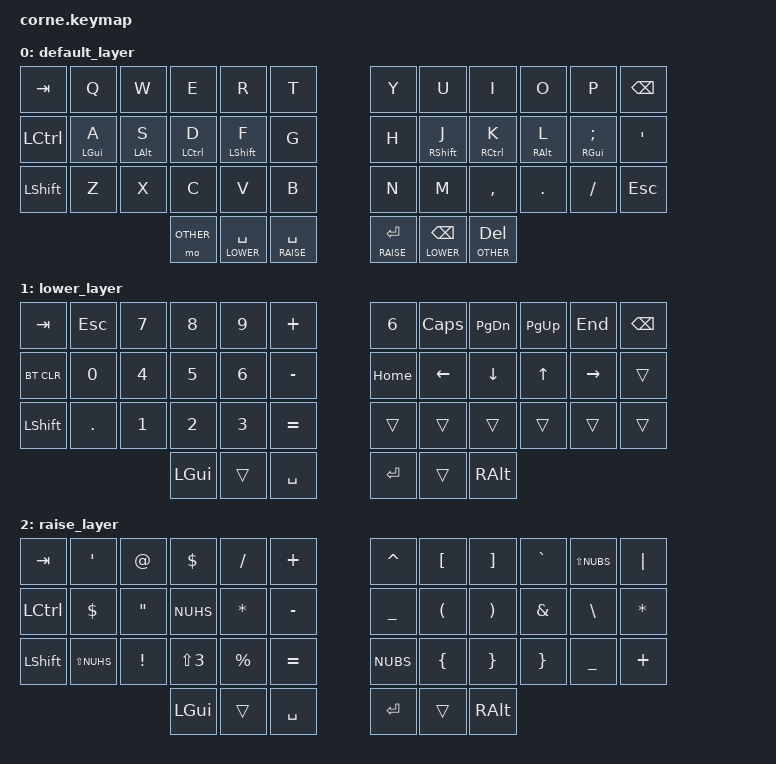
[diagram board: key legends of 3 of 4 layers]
/*
 * Copyright (c) 2020 The ZMK Contributors
 *
 * SPDX-License-Identifier: MIT
 */

#include <behaviors.dtsi>
#include <dt-bindings/zmk/keys.h>
#include <dt-bindings/zmk/bt.h>
#include <dt-bindings/zmk/outputs.h>

#define DEFAULT 0
#define LOWER   1
#define RAISE   2
#define OTHER   3

&lt {
    quick-tap-ms = <200>;
    tapping-term-ms = <200>;
};

/ {
    behaviors {
        hm: homerow_mods {
            compatible = "zmk,behavior-hold-tap";
            #binding-cells = <2>;
            tapping-term-ms = <200>;
            quick-tap-ms = <200>;
            require-prior-idle-ms = <125>;
            flavor = "tap-preferred";
            bindings = <&kp>, <&kp>;
        };
    };
    combos {
        compatible = "zmk,combos";
        combo_tab {
            timeout-ms = <50>;
            key-positions = <7 8>;
            bindings = <&kp TAB>;
        };
        combo_esc { 
            timeout-ms = <50>;
            key-positions = <3 4>;
            bindings = <&kp ESC>;
        };
        combo_caps_wd { 
            timeout-ms = <50>;
            key-positions = <2 3>;
            bindings = <&caps_word>;
        };
        combo_caps { 
            timeout-ms = <50>;
            key-positions = <8 9>;
            bindings = <&kp CAPS>;
        };
    };

        keymap {
                compatible = "zmk,keymap";

                default_layer {
                        bindings = <
   &kp TAB   &kp Q      &kp W      &kp E       &kp R        &kp T   &kp Y &kp U         &kp I           &kp O        &kp P         &kp BSPC
   &kp LCTRL &hm LGUI A &hm LALT S &hm LCTRL D &hm LSHIFT F &kp G   &kp H &hm RSHIFT J  &hm RCTRL K     &hm RALT L   &hm RGUI SEMI &kp SQT
   &kp LSHFT &kp Z      &kp X      &kp C       &kp V        &kp B   &kp N &kp M         &kp COMMA       &kp DOT      &kp FSLH      &kp ESC
                  &mo OTHER &lt LOWER SPACE &lt RAISE SPACE   &lt RAISE RET &lt LOWER BKSP &lt OTHER DEL
                        >;
                };
                lower_layer {
                        bindings = <
   &kp TAB    &kp ESC    &kp N7       &kp N8       &kp N9       &kp PLUS      &kp N6   &kp CAPS   &kp PG_DN   &kp PG_UP    &kp END     &kp BSPC
   &bt BT_CLR &kp N0     &kp N4       &kp N5       &kp N6       &kp MINUS     &kp HOME &kp LEFT   &kp DOWN    &kp UP       &kp RIGHT   &trans
   &kp LSHFT  &kp DOT    &kp N1       &kp N2       &kp N3       &kp EQUAL     &trans   &trans     &trans      &trans       &trans      &trans
                                    &kp LGUI     &trans       &kp SPACE      &kp RET  &trans   &kp RALT
                        >;
                };

                raise_layer {
                        bindings = <
   &kp  TAB  &kp SQT        &kp AT   &kp DLLR     &kp SLASH   &kp PLUS       &kp CARET &kp LBKT  &kp RBKT  &kp GRAVE &kp LS(NUBS)  &kp PIPE
   &kp LCTRL &kp DLLR       &kp DQT  &kp NUHS     &kp ASTRK   &kp MINUS      &kp UNDER &kp LPAR  &kp RPAR  &kp AMPS  &kp BSLH      &kp ASTRK
   &kp LSHFT &kp LS(NUHS)   &kp EXCL &kp LS(N3)   &kp PRCNT   &kp EQUAL      &kp NUBS  &kp LBRC  &kp RBRC  &kp RBRC  &kp UNDER     &kp PLUS
                             &kp LGUI &trans   &kp SPACE   &kp RET   &trans    &kp RALT
                        >;
                };

                other_layer {
                        bindings = <
   &kp  TAB  &kp F2         &kp F3    &kp F4          &kp F5         &kp F6               &kp F7    &kp F8    &kp F9    &kp F10   &kp F11   &kp PIPE
   &kp LCTRL &kp F1         &kp DQT   &kp HASH        &kp ASTRK      &kp MINUS            &kp UNDER &kp LPAR  &kp RPAR  &kp AMPS  &kp F12   &kp ASTRK
   &kp LSHFT &kp LS(NUHS)   &kp EXCL  &out OUT_USB    &out OUT_BLE   &kp &bootloader      &bt BT_CLR  &bt BT_SEL 0  &bt BT_SEL 1  &kp RBRC  &kp UNDER &kp PLUS
                             &trans &trans   &trans   &trans   &trans    &trans
                        >;
                };
        };
};
